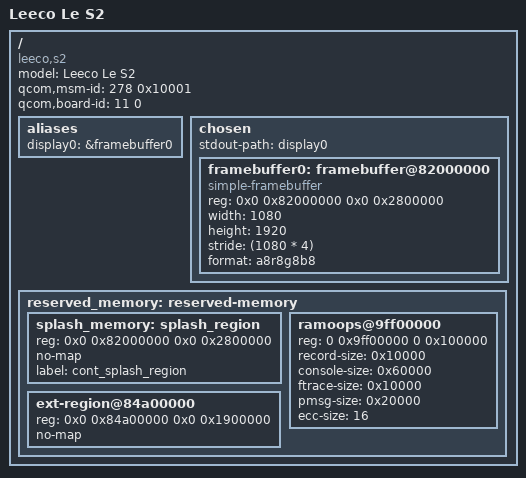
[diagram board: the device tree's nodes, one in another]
/dts-v1/;
#include "msm8976.dtsi"
#include "pm8950.dtsi"
#include "pm8004.dtsi"
#include "pmi8950.dtsi"
#include <dt-bindings/interrupt-controller/irq.h>
#include <dt-bindings/gpio/gpio.h>
#include <dt-bindings/input/gpio-keys.h>
#include <dt-bindings/input/input.h>
#include <dt-bindings/input/linux-event-codes.h>
#include <dt-bindings/pinctrl/qcom,pmic-gpio.h>
#include <dt-bindings/leds/common.h>
#include <dt-bindings/input/ti-drv260x.h>

/delete-node/ &ext-region@85b00000;

/ {
	model = "Leeco Le S2";
	compatible = "leeco,s2", "qcom,msm8976";

	qcom,msm-id = <278 0x10001>;
	qcom,board-id = <11 0>;

	aliases {
		display0 = &framebuffer0;
	};

	chosen {
		#address-cells = <2>;
		#size-cells = <2>;
		ranges;

		stdout-path = "display0";

		framebuffer0: framebuffer@82000000 {
			compatible = "simple-framebuffer";
			reg = <0x0 0x82000000 0x0 0x2800000>;
			width = <1080>;
			height = <1920>;
			stride = <(1080 * 4)>;
			format = "a8r8g8b8";
		};
	};

        reserved_memory: reserved-memory {
		#address-cells = <2>;
		#size-cells = <2>;
		ranges;

                splash_memory:splash_region {
                        reg = <0x0 0x82000000 0x0 0x2800000>;
                        no-map;
                        label = "cont_splash_region";
                };

		ext-region@84a00000 {
			reg = <0x0 0x84a00000 0x0 0x1900000>;
			no-map;
		};

                ramoops@9ff00000 {
                        reg = <0 0x9ff00000 0 0x100000>;
			record-size = <0x10000>;
			console-size = <0x60000>;
			ftrace-size = <0x10000>;
			pmsg-size = <0x20000>;
			ecc-size = <16>;
                };
	};
};
